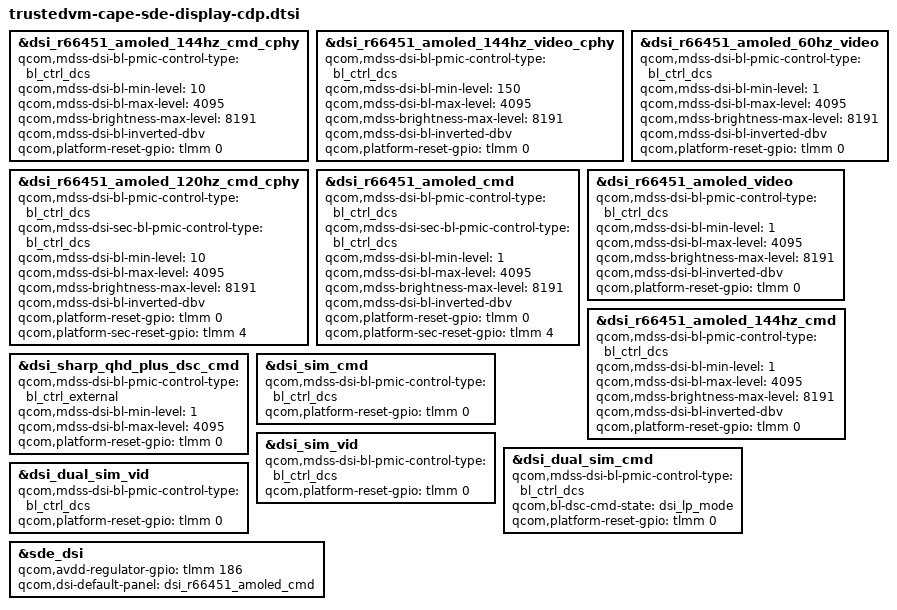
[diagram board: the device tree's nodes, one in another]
#include "trustedvm-cape-sde-display.dtsi"

&dsi_r66451_amoled_144hz_cmd_cphy {
	qcom,mdss-dsi-bl-pmic-control-type = "bl_ctrl_dcs";
	qcom,mdss-dsi-bl-min-level = <10>;
	qcom,mdss-dsi-bl-max-level = <4095>;
	qcom,mdss-brightness-max-level = <8191>;
	qcom,mdss-dsi-bl-inverted-dbv;
	qcom,platform-reset-gpio = <&tlmm 0 0>;
};

&dsi_r66451_amoled_144hz_video_cphy {
	qcom,mdss-dsi-bl-pmic-control-type = "bl_ctrl_dcs";
	qcom,mdss-dsi-bl-min-level = <150>;
	qcom,mdss-dsi-bl-max-level = <4095>;
	qcom,mdss-brightness-max-level = <8191>;
	qcom,mdss-dsi-bl-inverted-dbv;
	qcom,platform-reset-gpio = <&tlmm 0 0>;
};

&dsi_r66451_amoled_120hz_cmd_cphy {
	qcom,mdss-dsi-bl-pmic-control-type = "bl_ctrl_dcs";
	qcom,mdss-dsi-sec-bl-pmic-control-type = "bl_ctrl_dcs";
	qcom,mdss-dsi-bl-min-level = <10>;
	qcom,mdss-dsi-bl-max-level = <4095>;
	qcom,mdss-brightness-max-level = <8191>;
	qcom,mdss-dsi-bl-inverted-dbv;
	qcom,platform-reset-gpio = <&tlmm 0 0>;
	qcom,platform-sec-reset-gpio = <&tlmm 4 0>;
};

&dsi_r66451_amoled_cmd {
	qcom,mdss-dsi-bl-pmic-control-type = "bl_ctrl_dcs";
	qcom,mdss-dsi-sec-bl-pmic-control-type = "bl_ctrl_dcs";
	qcom,mdss-dsi-bl-min-level = <1>;
	qcom,mdss-dsi-bl-max-level = <4095>;
	qcom,mdss-brightness-max-level = <8191>;
	qcom,mdss-dsi-bl-inverted-dbv;
	qcom,platform-reset-gpio = <&tlmm 0 0>;
	qcom,platform-sec-reset-gpio = <&tlmm 4 0>;
};

&dsi_r66451_amoled_60hz_video {
	qcom,mdss-dsi-bl-pmic-control-type = "bl_ctrl_dcs";
	qcom,mdss-dsi-bl-min-level = <1>;
	qcom,mdss-dsi-bl-max-level = <4095>;
	qcom,mdss-brightness-max-level = <8191>;
	qcom,mdss-dsi-bl-inverted-dbv;
	qcom,platform-reset-gpio = <&tlmm 0 0>;
};

&dsi_r66451_amoled_video {
	qcom,mdss-dsi-bl-pmic-control-type = "bl_ctrl_dcs";
	qcom,mdss-dsi-bl-min-level = <1>;
	qcom,mdss-dsi-bl-max-level = <4095>;
	qcom,mdss-brightness-max-level = <8191>;
	qcom,mdss-dsi-bl-inverted-dbv;
	qcom,platform-reset-gpio = <&tlmm 0 0>;
};

&dsi_r66451_amoled_144hz_cmd {
	qcom,mdss-dsi-bl-pmic-control-type = "bl_ctrl_dcs";
	qcom,mdss-dsi-bl-min-level = <1>;
	qcom,mdss-dsi-bl-max-level = <4095>;
	qcom,mdss-brightness-max-level = <8191>;
	qcom,mdss-dsi-bl-inverted-dbv;
	qcom,platform-reset-gpio = <&tlmm 0 0>;
};

&dsi_sharp_qhd_plus_dsc_cmd {
	qcom,mdss-dsi-bl-pmic-control-type = "bl_ctrl_external";
	qcom,mdss-dsi-bl-min-level = <1>;
	qcom,mdss-dsi-bl-max-level = <4095>;
	qcom,platform-reset-gpio = <&tlmm 0 0>;
};

&dsi_sim_cmd {
	qcom,mdss-dsi-bl-pmic-control-type = "bl_ctrl_dcs";
	qcom,platform-reset-gpio = <&tlmm 0 0>;
};

&dsi_sim_vid {
	qcom,mdss-dsi-bl-pmic-control-type = "bl_ctrl_dcs";
	qcom,platform-reset-gpio = <&tlmm 0 0>;
};

&dsi_dual_sim_cmd {
	qcom,mdss-dsi-bl-pmic-control-type = "bl_ctrl_dcs";
	qcom,bl-dsc-cmd-state = "dsi_lp_mode";
	qcom,platform-reset-gpio = <&tlmm 0 0>;
};

&dsi_dual_sim_vid {
	qcom,mdss-dsi-bl-pmic-control-type = "bl_ctrl_dcs";
	qcom,platform-reset-gpio = <&tlmm 0 0>;
};

&sde_dsi {
	qcom,avdd-regulator-gpio = <&tlmm 186 0>;
	qcom,dsi-default-panel = <&dsi_r66451_amoled_cmd>;
};
